# LEA_367.0 register map
Vendor: Texas Instruments
Peripheral module from a debugger description file (folder msp430).
Registers are 32-bit, read-write, no defined reset value unless marked. A register's access mark holds for its fields unless they carry their own. Offsets are as the file gives them; lines under a group give offsets from that group; [hi:lo] are bit positions; {n}, {i} and the like mark numbered series; 'fields as' and 'values as' point back to an identical list; <NAME> marks a mode.

## LEA
0x00 LEACAP ro — LEA Capability Register
  [3:0] LEAMSIZ — LEA Code Memory Size. This register identifies the size of available code RAM.
    0=no code RAM; 1=1KB Code RAM
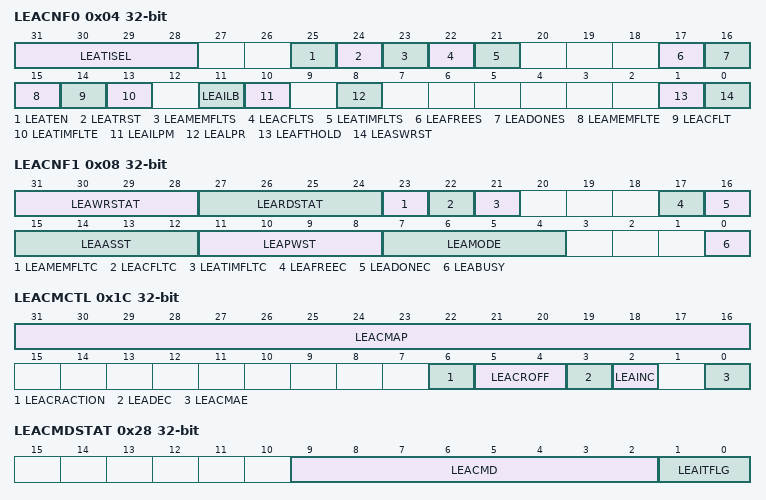
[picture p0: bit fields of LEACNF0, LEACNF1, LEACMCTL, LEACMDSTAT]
0x04 LEACNF0 access per field — Configuration Register 0
  [31:28] LEATISEL rw — LEA timer interval select. These bits select LEA timer interval. t#sub#CLK#/sub# = 1 / f#sub#CLK#/sub# f#sub#CLK#/sub# = MCLK
    0=Timeout period: 128 x t#sub#CLK#/sub# (16 us at 8 MHz); Interval period: 256 x t#sub#CLK#/sub# (32 us at 8 MHz); 1=Timeout period: 256 x t#sub#CLK#/sub# (32 us at 8 MHz); Interval period: 512 x t#sub#CLK#/sub# (64 us at 8 MHz); 2=Timeout period: 512 x t#sub#CLK#/sub# (64 us at 8 MHz); Interval period: 1024 x t#sub#CLK#/sub# (128 us at 8 MHz); 3=Timeout period: 1024 x t#sub#CLK#/sub# (128 us at 8 MHz); Interval period: 2048 x t#sub#CLK#/sub# (256 us at 8 MHz); 4=Timeout period: 2048 x t#sub#CLK#/sub# (256 us at 8 MHz); Interval period: 4096 x t#sub#CLK#/sub# (512 us at 8 MHz); 5=Timeout period: 4096 x t#sub#CLK#/sub# (512 us at 8 MHz); Interval period: 8192 x t#sub#CLK#/sub# (1ms at 8 MHz); 6=Timeout period: 8192 x t#sub#CLK#/sub# (1 ms at 8 MHz); Interval period: 16384 x t#sub#CLK#/sub# (2 ms at 8 MHz); 7=Timeout period: 16384 x t#sub#CLK#/sub# (2 ms at 8 MHz); Interval period: 32768 x t#sub#CLK#/sub# (4 ms at 8 MHz); 8=Timeout period: 32768 x t#sub#CLK#/sub# (4ms at 8 MHz); Interval period: 65536 x t#sub#CLK#/sub# (8 ms at 8 MHz); 9=Timeout period: 65536 x t#sub#CLK#/sub# (8 ms at 8 MHz); Interval period: 131072 x t#sub#CLK#/sub# (16 ms at 8 MHz); 10=Timeout period: 131072 x t#sub#CLK#/sub# (16 ms at 8 MHz); Interval period: 262144 x t#sub#CLK#/sub# (32 ms at 8 MHz); 11=Timeout period: 524288 x t#sub#CLK#/sub# (65 ms at 8 MHz); Interval period: 1048576 x t#sub#CLK#/sub# (131 ms at 8 MHz); 12=Timeout period: 1048576 x t#sub#CLK#/sub# (131 ms at 8 MHz); Interval period: 2097152 x t#sub#CLK#/sub# (262 ms at 8 MHz); 13=Timeout period: 2097152 x t#sub#CLK#/sub# (262 ms at 8 MHz); Interval period: 4194304 x t#sub#CLK#/sub# (524 ms at 8 MHz); 14=Timeout period: 4194304 x t#sub#CLK#/sub# (524 ms at 8 MHz); Interval period: 8388608 x t#sub#CLK#/sub# (1.05 s at 8 MHz); 15=Timeout period: 8388608 x t#sub#CLK#/sub# (1.05 s at 8 MHz); Interval period: 16777216 x t#sub#CLK#/sub# (2.1 s at 8 MHz)
  [25] LEATEN rw — LEA timer enable; writing a one to this bit enables LEA timer operations.
  [24] LEATRST rw — LEA module timer reset. Setting this bit to one clears LEA module timer. This bit is self clearing and will always be read as zero.
  [23] LEAMEMFLTS rw — LEA memory fault indication and set flag. This bit indicates that a fault in the memory VBUS interface occurred. The exact fault reason may be identified by checking LEACNF1. LEAWRSTAT and LEACNF1.LEARDSTAT.
    0=No memory fault occurred since this bit was cleared; 1=At least one memory fault since this bit was cleared
  [22] LEACFLTS rw — LEAHPCFLTS when hardware trigger enabled later LEA command fault on peripheral interface or hardware triggered indication and set flag; This bits indicates that a command was invoked that is not implemented. This fault is also signaled to the SYS module as a "User-NMI" when enabled. Only one fault condition is signaled until this bit is cleared. Leaving this bit set will not cause any further faults. This fault may also be set by writing a one to it. Writing a zero has no effect.The corresponding terminal is connected to one of the UNMI inputs of the SYS module.
    0=No command fault occurred since this bit was cleared; 1=At least one command fault occurred since this bit was cleared
  [21] LEATIMFLTS rw — LEA timeout fault indication and set flag; This bits indicates that timer timeout occurred. This fault may also be set by writing a one to it. Writing a zero has no effect.The corresponding terminal is connected to one of the UNMI inputs of the SYS module (A package option)
  [17] LEAFREES rw — LEA free event indication and set flag. This bit indicated the free event for LEA. This bit can be set by writing a one to it. Writing a zero has no effect.
  [16] LEADONES rw — LEA done event indication and set flag. This bit indicated the done event for LEA. This bit can be set by writing a one to it. Writing a zero has no effect.
  [15] LEAMEMFLTE rw — Enable bit on memory faults.
    0=LEA memory faults are disabled; 1=LEA memory faults are enabled
  [14] LEACFLT rw — LEAHPCFLTE when hardware trigger available later Enable bit on peripheral mapped command faults and hardware triggered command faults.
    0=LEAHPCFLT is disabled; 1=LEAHPCFLT is enabled
  [13] LEATIMFLTE rw — LEA module timer fault enable.
    0=LEATIMFLT_0 (LEA module timer timeout will not cause a fault indication); 1=LEA module timer timeout will cause a fault indication. LEA stops operation and enters "Ready-state".
  [11] LEAILB ro — LEA instruction loop buffer disable. Debugging function for LEA (leave it zero).
  [10] LEAILPM rw — This bit defines if a "Command done interrupt" shall be triggered in LPM mode
    0=Interrupt of LEA is suppressed in LPM mode until AM is entered then the LEA interrupt is triggered as well; 1=Interrupt of LEA is always triggered on completion of an LEA command
  [8] LEALPR rw — This bit defined if command execution shall be continued in LPM modes
    0=LEA command execution stops in deep low power modes; 1=LEA command execution continues in deep low power modes
  [1] LEAFTHOLD rw — Hold on faults and NMIs for all pending LEA operations transfers.This is for all system wide fault/NMI cases (for our first implementation we may just consider local LEA triggered fault cases)
    0=LEA transfers continue on faults/NMIs; 1=LEA transfers enter HOLD on faults/NMIs
  [0] LEASWRST rw — LEA module software restart. Setting this bit to one restarts the LEA module. As long this bit remains set to one the LEA is held in Restart. (The LEA accessible memory behaves as system RAM)
0x08 LEACNF1 access per field — Configuration Register 1
  [31:28] LEAWRSTAT ro — Write Status. This bit field keeps the VBUS write status lines from the last bus error condition.
  [27:24] LEARDSTAT ro — Read Status. This bit field keeps the VBUS read status lines from the last bus error condition.
  [23] LEAMEMFLTC rw — LEA memory fault indication and clear flag. This bit indicates that a fault in the memory VBUS interface occurred. The exact fault reason may be identified by checking LEAWRSTAT and LEARDSTAT. This fault is also signaled to the SYS-module as bus error when enabled (LEACNF0.LEAMEMFLTE=1). Only one fault condition is signaled until this bit is cleared. Leaving this bit set will not cause any further faults. This fault is cleared by writing a one to it. Writing a zero has no effect.
    values as LEACNF0.LEAMEMFLTS
  [22] LEACFLTC rw — LEA command fault
    values as LEACNF0.LEACFLTS
  [21] LEATIMFLTC rw — LEA timeout fault indication and clear flag; This bits indicates that a timer timeout occurred. This fault is cleared by writing a one to it. Writing a zero has no effect..
  [17] LEAFREEC rw — LEA free event indication and clear flag. This bit indicated the free event for LEA. This bit is cleared by writing a one to it. Writing a zero has no effect.
  [16] LEADONEC rw — LEA done event indication and clear flag. This bit indicated the done event for LEA. This bit is cleared by writing a one to it. Writing a zero has no effect.
  [15:12] LEAASST ro — These bits are used to store the internal state of the application specific processor (ASIP) inside the accelerator core. The specific meaning of those bit patterns is not shown in this document.
  [11:8] LEAPWST ro — These bits indicate the current power consumption as a relative value. The value zero indicated only static operation (usually clock less). This register might be read out for statistical power estimation of an application. These bits are also reflected in J-STATE when debugging
  [7:4] LEAMODE ro — These Bits indicate the actual operation mode LEA is in. Other = Reserved
    0=OFF (Off (implicit)); 1=READY; 2=RUNS (RunS (SUSPEND)); 3=RUNR (RunR (RESUME)); 4=RUNA (RunA (regular command operation )); 5=NOTIFY; 6=SLEEP; 7=RUNL
  [0] LEABUSY ro — This bit indicate if LEA is able to accept new Commands (SUSPEND is always accepted)
    0=READY (LEA is in Ready can accept new commands); 1=BUSY (LEA is busy right now and cannot accept any commands)
0x0C LEACNF2 — Configuration Register 2
  [15:0] LEASPTR — LEA stack pointer value (byte units). 64 lower kB is physical limit for LEA application complexity
0x10 LEAMB ro — Memory Bottom Register
  [15:0] LEAMB — LEA memory bottom address boundary in byte address units
0x14 LEAMT ro — Memory Top Register
  [15:0] LEAMT — LEA memory top address boundary in byte address units
0x18 LEACMA access not given — Code Memory Access Register
0x1C LEACMCTL — Code Memory Control Register
  [31:16] LEACMAP — LEA code memory address port. This bit field points to the memory location that is accessible via LEACMDP
  [6] LEACRACTION — Code RAM action
  [5:4] LEACROFF — Control bits only available if LEA code RAM is available. Otherwise reserved. Reserved. Read back as 0
    0=Contents of LEA code RAM are retained in LPM3/LPM4; 1=Turns off the LEA code RAM in LPM3/LPM4, re-activates it on wake-up. All data of the code RAM is lost after wakeup from LPM3/LPM4. See the device specific data sheet for presence and size of Code RAM.; 2=Turns off the code RAM entering LPM3/LPM4, the code RAM sector remains off after wake-up. All data of the code RAM is lost. See the device-specific data sheet for presence and size of Code RAM.
  [3] LEADEC — This bit when set causes the code memory address port field LEACMAP to decrement each time after an access to LEACMDP is performed.The decrement is by value two on 16B accesses on lower word of LEACMA.The decrement is by value two on 32B accesses on LEACMA.#b#Note:#/b# A double decrement is performed when read modify write accesses are done on LEACMDP.
  [2] LEAINC — This bit when set causes the code memory address port field LEACMAP to increment each time after an access to LEACMDP is performed.The decrement is by value two on 16B accesses on lower word of LEACMA.The decrement is by value two on 32B accesses on LEACMA.#b#Note:#/b# A double increment is performed when read modify write accesses are done on LEACMDP.
  [0] LEACMAE — This bit controls access to LEA code memory.
    0=Code memory access disabled. Accesses to LEA code memory are not possible. LEA does accept commands for execution. Reads to LEA code memory will return zeroes and writes are ignored.; 1=Code memory access enabled. Accesses to LEA code memory are possible. LEA does not accept commands during this mode (command is ignored). Coprocessor interface accesses by the CPU cause a Coprocessor not available indication.
0x28 LEACMDSTAT ro — LEA Command Status Register
  [9:2] LEACMD — These bits represent the LEA command to be invoked. See also the command table
    0=SUSPEND (Suspends ongoing action an enters Ready); 2=RESUME (Resumes an previously suspended command execution); 4=FFTCOMPLEXFIXEDSCALING (Complex FFT on 16 bit fractional numbers fix scaling); 6=FIR (Real FIR on 16 bit fractional numbers); 8=POLYNOMIAL (Real vector polynomial calculations 16 args all fractional); 10=FFT (Real FFT-extension on 16 bit fractional numbers); 12=POLYNOMIALLONG (Real vector polynomial calculations 32 bit args all fractional); 13=MPYMATRIXROW (Real row oriented matrix multiply); 15=MPYMATRIX (Real matrix multiply 16 with 16 to 16 bit fractional); 16=ADDMATRIX (Real point wise matrix add of 16 and 16 to 16 bit number vector); 17=MAXMATRIX (Real maximum value and position of 16 bit matrices); 18=MINMATRIX (Real minimum value and position of 16 bit matrices); 19=IIRBQ1 (Real second order biquad using DF1 with 16 bit fractional); 21=MAC (Real matrix MAC short with 16Bt to 16B fract); 22=DEINTERLEAVEEVENEVEN (Split 16B vector even to even words); 23=DEINTERLEAVEEVENODD (Split 16Bt vector even to odd words); 24=DEINTERLEAVEODDEVEN (Split 16B vector odd to even words); 25=DEINTERLEAVEODDODD (Split 16B vector odd to odd words); 26=MACCOMPLEXMATRIX (Complex Dot Product); 27=MACCOMPLEXCONJUGATEMATRIX (Complex conjugate Dot Product); 28=SUBMATRIX (Real point wise matrix Subtraction of 16 and 16 to 16 bit); 29=MPYLONGMATRIX (Real point wise matrix multiply 32 with 32 to 32 bit fractional); 30=MPYCOMPLEXMATRIX (Complex point wise matrix multiply complex with complex); 31=ADDLONGMATRIX (Real point wise matrix add of 32 and 32 to 32 bit number); 32=MOVELONGLIST (List move 32 to 32 bit); 33=BITREVERSECOMPLEXEVEN (Complex bit reversal for 16 bit fractional numbers even); 34=BITREVERSECOMPLEXODD (Complex bit reversal for 16 bit fractional Numbers odd); 36=IIRBQ2EXTENDED (Real second order biquad using DF2 with 16 bit fractional, extended to include bias and intermediate state min/max); 39=FFTCOMPLEXLONG (Complex FFT on 32B bit fractional numbers, fix scaling); 41=FFTLONG (Real FFT-extension on 32 bit fractional numbers); 43=BITREVERSECOMPLEXLONGEVEN (Complex bit reversal for 32 bit fractional numbers even); 45=BITREVERSECOMPLEXLONGODD (Complex bit reversal for 16 bit fractional numbers odd); 47=POLYNOMIALSCALAR (Scalar Polynomial for math on 32bit fractional); 48=FFTCOMPLEXAUTOSCALING (Complex FFT on 16B bit fractional numbers with auto scaling for enhanced accuracy); 50=FIRLONG (Real FIR on 32 bit fractional numbers); 52=MACLONGMATRIX (Real block MAC on 32B fractional numbers); 53=SUBLONGMATRIX (Real point wise matrix Subtraction of 32 and 32 to 32 bit); 54=MAXLONGMATRIX (Real maximum value and position of signed 32B matrices); 55=MINLONGMATRIX (Real minimum value and position of signed 32B matrices); 56=FIRCOMPLEX (Complex FIR on 16B fractional numbers); 58=MAXUNSIGNEDMATRIX (Real maximum value and position of unsigned 16B matrices); 59=MINUNSIGNEDMATRIX (Real minimum value and position of unsigned 32B matrices); 64=MACMATRIX (Real Matrix MAC on 16B fractional); 65=MAX (Vector maximum on 16B signed numbers); 66=MIN (Vector minimum on 16B signed numbers); 67=MAXUNSIGNED (Vector maximum on 16B unsigned numbers); 68=MINUNSIGNED (Vector minimum on 16B unsigned numbers); 69=MAXUNSIGNEDLONGMATRIX (Matrix maximum on 32B unsigned numbers); 70=MINUNSIGNEDLONGMATRIX (Matrix minimum on 32B unsigned numbers); 71=IIRBQ2 (Real second order biquad using DF2 with 16 bit fractional); 73=FIRCOMPLEXLONG (Complex FIR on 32B fractional numbers); 75=DEINTERLEAVELONG (Split Function on 32B Vectors/Matrices); 76=WINDOW (In-place symmetrical window on 16B fractional numbers); 77=MAC3 (Vector MAC at three points, real 16-bit with 32-bit result); 78=SCALEDMAC (Scaled vector multiply and accumulate (MAC)); 79=SCALEDFIR (Scaled FIR, 16-bit real fractional numbers)
  [1:0] LEAITFLG — LEA instruction handshake synchronization type flags
    0=LEA command without any further indication; 1=LEA command with explicit result update; 2=LEA command with interrupt upon completion; 3=LEA command with interrupt and explicit result update
0x2C LEAS1STAT access not given — LEA Source 1 Status Register
0x30 LEAS0STAT access not given — LEA Source 0 Status Register
0x34 LEADSTSTAT access not given — LEA Result Status Register
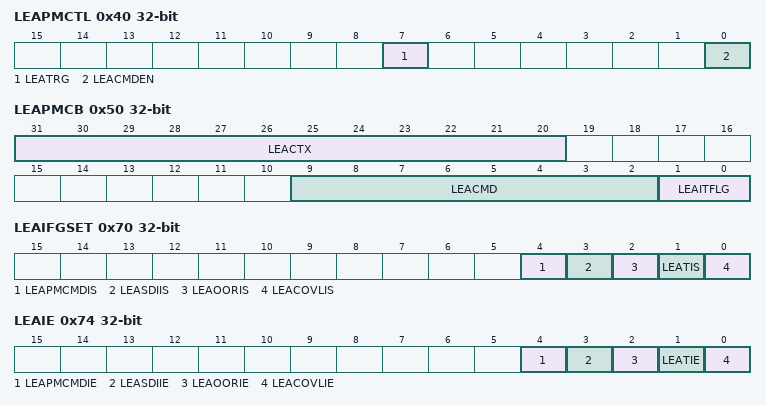
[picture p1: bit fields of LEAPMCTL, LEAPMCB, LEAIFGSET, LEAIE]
0x40 LEAPMCTL access per field — PM Control Register
  [7] LEATRG ro — Command trigger
  [0] LEACMDEN rw — Command enable
    0=Command triggering by writing to LEAPMCB is disabled; 1=Command triggering by writing to LEAPMCB is enabled
0x44 LEAPMDST access not given — PM Result Register
0x48 LEAPMS1 access not given — PM Source 1 Register
0x4C LEAPMS0 access not given — PM Source 0 Register
0x50 LEAPMCB — PM Command Buffer Register
  [31:20] LEACTX — Command context: This bit field may be set by the user together with invoking a command. This bit field is saved on SUSPEND; and restored from LEA Stack on RESUME. This bit field is used by SW to associate or synchronize LEA commands to a certain tasks and IDs.
  [9:2] LEACMD — These bits represent the LEA command to be invoked. See also the command table
    values as LEACMDSTAT.LEACMD
  [1:0] LEAITFLG — LEA instruction handshake synchronization type flag
    values as LEACMDSTAT.LEAITFLG
0x70 LEAIFGSET — Interrupt Flag and Set Register
  [all] fields
    0=No interrupt pending; 1=Interrupt pending
  [4] LEAPMCMDIS — PMCMD as soon hardware trigger is avail. Peripheral memory triggered Command completed interrupt flag.
  [3] LEASDIIS — LEA scalar data inconsistency interrupt flag
  [2] LEAOORIS — LEA out of address range interrupt flag.
  [1] LEATIS — LEA timer interrupt flag
  [0] LEACOVLIS — LEA command overflow interrupt flag
0x74 LEAIE — Interrupt Enable Register
  [all] fields
    0=Interrupt disabled; 1=Interrupt enabled
  [4] LEAPMCMDIE — PMCMD as soon hardware trigger is avail. Peripheral memory triggered Command completed interrupt enable.
  [3] LEASDIIE — LEA scalar data inconsistency interrupt enable
  [2] LEAOORIE — LEA out of address range interrupt enable.
  [1] LEATIE — LEA timer event interrupt enable
  [0] LEACOVLIE — LEA command overflow interrupt enable
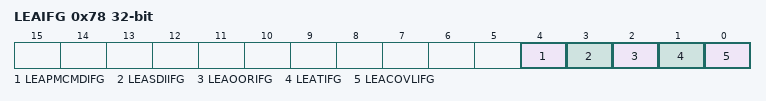
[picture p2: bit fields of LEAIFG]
0x78 LEAIFG — Interrupt Flag and Clear Register
  [all] fields
    0=No interrupt pending; 1=Interrupt pending
  [4] LEAPMCMDIFG — PMCMD when hardware trigger is available. Peripheral memory triggered Command completed interrupt flag.
  [3] LEASDIIFG — LEA scalar data inconsistency interrupt flag
  [2] LEAOORIFG — LEA out of address range interrupt flag.
  [1] LEATIFG — LEA timer interrupt flag
  [0] LEACOVLIFG — LEA command overflow interrupt flag
0x7C LEAIV — Interrupt Vector Register
  [7:0] LEAIV — LEA interrupt vector. This is a generated value that can be used as address offset for fast interrupt service routine handling. Reading this register clears the highest pending LEA interrupt (displaying this register with an IDE does not affect its content). Writing to this register clears al pending interrupt flags.This value is always aligned to a 20 bit address offset boundary
    0=NONE (No interrupt pending); 2=COVLIFG (LEA command overflow); 4=TIFG (LEA timer interrupt); 6=OORIFG (LEA out of range interrupt); 8=SDIIFG (LEA scalar data inconsistency); 10=PMCMDIFG (PMCMD complete interrupt)
